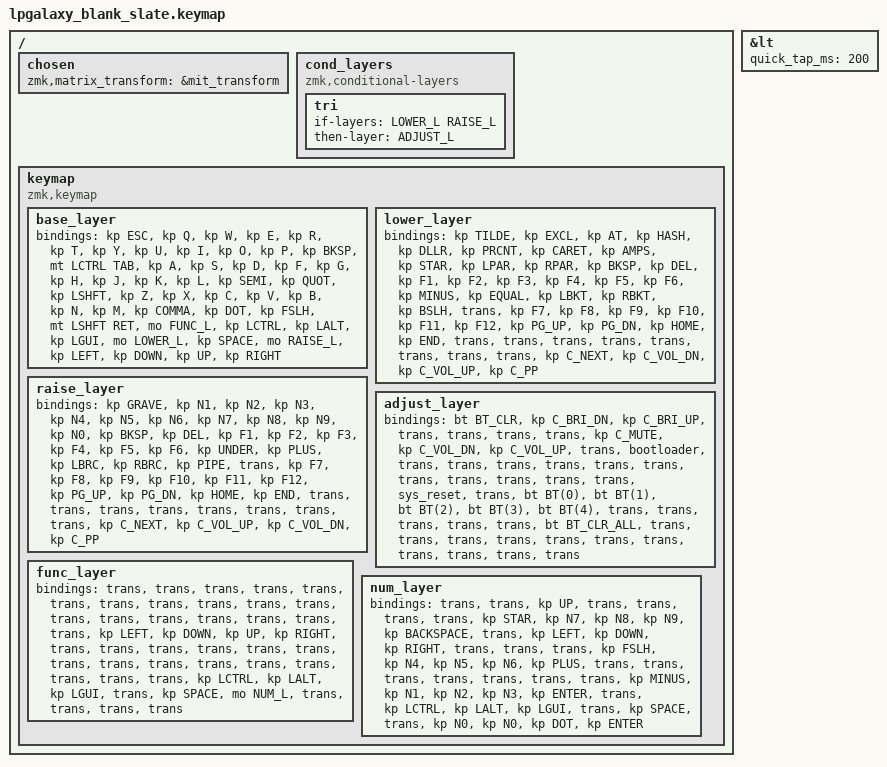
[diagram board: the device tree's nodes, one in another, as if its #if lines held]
/*
 * Copyright (c) 2022 Pete Johanson
 *
 * SPDX-License-Identifier: MIT
 */

#include <behaviors.dtsi>
#include <dt-bindings/zmk/keys.h>
#include <dt-bindings/zmk/bt.h>
#include <dt-bindings/zmk/outputs.h>

//#define QWERTY_BASE 1

#define TBLE_ORTHO   1
// #define TBLE_MIT     1
// #define TBLE_DUAL_2U 1

#define LOWER_L 1
#define RAISE_L 2
#define ADJUST_L 3
#define FUNC_L 4
#define NUM_L 5

// Using layer taps on thumbs, having quick tap as well helps w/ repeating space/backspace
&lt { quick_tap_ms = <200>; };

#define BT(n) BT_SEL n

/ {
    chosen {
       zmk,matrix_transform =
#ifdef TBLE_MIT
                       &mit_transform;
#else
                       &ortho_transform;
#endif
    };

// Conditional layer only when we have less thumb keys
    cond_layers {
        compatible = "zmk,conditional-layers";
	tri {
	    if-layers = <LOWER_L RAISE_L>;
	    then-layer = <ADJUST_L>;
        };
    };

    keymap {
        compatible = "zmk,keymap";

        base_layer {
            bindings = <
// -----------------------------------------------------------------------------------------------------------------------------------------------------------------------------------------------
//|      ESC      |       Q       |       W       |       E       |       R       |       T       |       Y       |       U       |       I       |       O       |       P       |     BKSP      |
       &kp ESC	        &kp Q	          &kp W	          &kp E	          &kp R	          &kp T	         &kp Y	          &kp U	          &kp I		        &kp O		        &kp P		       &kp BKSP
//|-----------------------------------------------------------------------------------------------------------------------------------------------------------------------------------------------|
//|  TAB / *LCTRL |       A       |       S       |       D       |       F       |       G       |       H       |       J       |       K       |       L       |       ;       |       '       |
    &mt LCTRL TAB	      &kp A	          &kp S	          &kp D	          &kp F	          &kp G	          &kp H	          &kp J	          &kp K		        &kp L		       &kp SEMI	       &kp QUOT
//|-----------------------------------------------------------------------------------------------------------------------------------------------------------------------------------------------|
//|     LSHIFT    |       Z       |       X       |       C       |       V       |       B       |       N       |       M       |       ,       |       .       |       /       |  ENT / *SHFT  |
       &kp LSHFT  	    &kp Z	          &kp X	          &kp C	          &kp V	          &kp B	          &kp N	          &kp M         &kp COMMA   	   &kp DOT    	   &kp FSLH	    &mt LSHFT RET
//|-----------------------------------------------------------------------------------------------------------------------------------------------------------------------------------------------|
#ifdef TBLE_MIT
//|      FN       |      CTRL     |      ALT      |    Win/Cmd    |     LOWER     |             SPACE             |     RAISE     |      LEFT     |     DOWN      |      UP       |     RIGHT     |
      &mo FUNC_L        &kp LCTRL       &kp LALT        &kp LGUI      &mo LOWER_L              &kp SPACE               &mo RAISE_L      &kp LEFT       &kp DOWN         &kp UP         &kp RIGHT
#else
//|-----------------------------------------------------------------------------------------------------------------------------------------------------------------------------------------------|
//|      FN       |      CTRL     |      ALT      |    Win/Cmd    |     LOWER     |      SPACE    |     SPACE     |     RAISE     |      LEFT     |     DOWN      |      UP       |     RIGHT     |
      &mo FUNC_L       &kp LCTRL       &kp LALT        &kp LGUI      &mo LOWER_L        &kp SPACE      &kp SPACE       &mo RAISE_L       &kp LEFT       &kp DOWN         &kp UP         &kp RIGHT
// -----------------------------------------------------------------------------------------------------------------------------------------------------------------------------------------------
#endif
            >;
        };

lower_layer {
            bindings = <
// ------------------------------------------------------------------------------------------------------------------------------------------------------------------------------------------
//|      ~      |       P       |       @       |       #       |       $       |       %       |      ^       |       &       |       *       |       (       |       )       |     BKSP    |
     &kp TILDE      &kp EXCL         &kp AT         &kp HASH        &kp DLLR        &kp PRCNT       &kp CARET       &kp AMPS        &kp STAR      &kp LPAR          &kp RPAR       &kp BKSP
//|------------------------------------------------------------------------------------------------------------------------------------------------------------------------------------------|
//|      DEL    |      F1       |       F2      |       F3      |       F4      |       F5      |       F6     |       -       |       =       |       (       |       }       |   BSLASH    |
       &kp DEL       &kp F1           &kp F2          &kp F3          &kp F4          &kp F5          &kp F6        &kp MINUS       &kp EQUAL        &kp LBKT        &kp RBKT     &kp BSLH
//|------------------------------------------------------------------------------------------------------------------------------------------------------------------------------------------|
//|             |      F7       |       F8      |       F9      |       F10     |       F11     |      F12     |       PUP     |       PDN     |       HOME    |       END     |             |
      &trans        &kp F7            &kp F8          &kp F9          &kp F10         &kp F11        &kp F12        &kp PG_UP       &kp PG_DN       &kp HOME        &kp END         &trans
//|------------------------------------------------------------------------------------------------------------------------------------------------------------------------------------------|
#ifdef TBLE_MIT
//|             |               |               |               |               |                              |               |      NEXT     |       VOL-    |      VOL+     |  Pause/Play |
        &trans        &trans          &trans         &trans          &trans                  &trans                 &trans          &kp C_NEXT    &kp C_VOL_DN    &kp C_VOL_UP    &kp C_PP
#else
//|------------------------------------------------------------------------------------------------------------------------------------------------------------------------------------------|
//|             |               |               |               |               |               |              |               |      NEXT     |       VOL-    |      VOL+     |  Pause/Play |
        &trans        &trans          &trans         &trans          &trans           &trans         &trans         &trans          &kp C_NEXT    &kp C_VOL_DN    &kp C_VOL_UP    &kp C_PP
// ------------------------------------------------------------------------------------------------------------------------------------------------------------------------------------------
#endif
            >;
        };

raise_layer {
            bindings = <
&kp GRAVE  &kp N1     &kp N2     &kp N3      &kp N4          &kp N5       &kp N6     &kp N7        &kp N8      &kp N9     &kp N0     &kp BKSP
&kp DEL     &kp F1     &kp F2    &kp F3      &kp F4          &kp F5       &kp F6     &kp UNDER       &kp PLUS    &kp LBRC     &kp RBRC  &kp PIPE
&trans     &kp F7  &kp F8  &kp F9   &kp F10       &kp F11    &kp F12     &kp PG_UP       &kp PG_DN   &kp HOME  &kp END    &trans
#ifdef TBLE_MIT
&trans  &trans        &trans     &trans      &trans                &trans             &trans      &kp C_NEXT         &kp C_VOL_UP &kp C_VOL_DN &kp C_PP
#else
&trans  &trans        &trans     &trans      &trans          &trans       &trans    &trans  &kp C_NEXT         &kp C_VOL_UP &kp C_VOL_DN &kp C_PP
#endif
            >;
        };
adjust_layer {

            bindings = <
&bt BT_CLR &kp C_BRI_DN     &kp C_BRI_UP     &trans      &trans          &trans       &trans     &kp C_MUTE         &kp C_VOL_DN      &kp C_VOL_UP     &trans     &bootloader 
&trans     &trans     &trans     &trans      &trans          &trans       &trans     &trans       &trans    &trans     &trans  &sys_reset
&trans     &bt BT(0)  &bt BT(1)  &bt BT(2)   &bt BT(3)       &bt BT(4)    &trans     &trans       &trans   &trans  &trans    &bt BT_CLR_ALL
#ifdef TBLE_MIT
&trans  &trans        &trans     &trans      &trans                &trans             &trans      &trans   &trans &trans &trans
#else
&trans  &trans        &trans     &trans      &trans          &trans       &trans    &trans  &trans         &trans &trans &trans
#endif
            >;
        };

func_layer {
            bindings = <
&trans &trans     &trans     &trans      &trans          &trans       &trans     &trans         &trans      &trans     &trans     &trans
&trans     &trans     &trans     &trans      &trans          &trans       &kp LEFT     &kp DOWN       &kp UP    &kp RIGHT     &trans  &trans
&trans     &trans  &trans  &trans   &trans       &trans    &trans     &trans       &trans   &trans  &trans    &trans
#ifdef TBLE_MIT
&trans  &kp LCTRL        &kp LALT     &kp LGUI      &trans                &kp SPACE             &mo NUM_L      &trans   &trans &trans &trans
#else
&trans  &kp LCTRL        &kp LALT     &kp LGUI      &trans          &kp SPACE       &kp SPACE    &mo NUM_L  &trans         &trans &trans &trans
#endif
            >;
        };

 num_layer {
            bindings = <
&trans &trans     &kp UP     &trans      &trans          &trans       &trans     &kp STAR         &kp N7      &kp N8     &kp N9     &kp BACKSPACE
&trans     &kp LEFT     &kp DOWN     &kp RIGHT      &trans          &trans       &trans     &kp FSLH       &kp N4    &kp N5     &kp N6  &kp PLUS
&trans     &trans  &trans  &trans   &trans       &trans    &trans     &kp MINUS       &kp N1   &kp N2  &kp N3    &kp ENTER
#ifdef TBLE_MIT
&trans  &kp LCTRL        &kp LALT     &kp LGUI      &trans                &kp SPACE             &trans      &kp N0         &kp N0 &kp DOT &kp ENTER
#else
&trans  &kp LCTRL        &kp LALT     &kp LGUI      &trans          &kp SPACE       &kp SPACE    &trans  &kp N0         &kp N0 &kp DOT &kp ENTER
#endif
            >;
        };

      

   
 
    };
};

